# STM32MP13xx register map
File version: 1.5
CPU: CA7 r0p0, little endian, MPU, FPU, 4 interrupt priority bits
Registers are 32-bit, read-write, reset 0x0 unless marked. A register's access mark holds for its fields unless they carry their own. Offsets are from the block's base; [hi:lo] are bit positions; {n}, {i} and the like mark numbered series; 'fields as' and 'values as' point back to an identical list.

## SYSCFG
Base 0x50020000
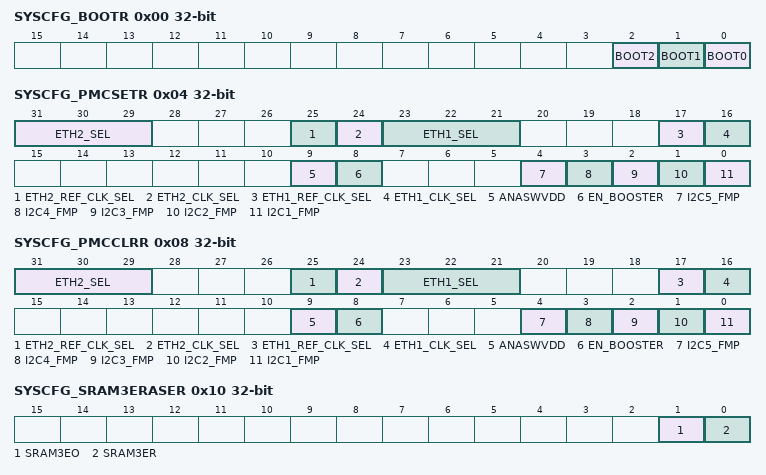
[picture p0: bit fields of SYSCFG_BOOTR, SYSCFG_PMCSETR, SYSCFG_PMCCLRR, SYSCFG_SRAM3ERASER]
0x00 SYSCFG_BOOTR ro (reset mask 0xFFFFFFF0) — SYSCFG boot pins control register
  [2] BOOT2 — BOOT2 pin value
    0=low (BOOT2 pin connected to VSS); 1=high (BOOT2 pin connected to VDD)
  [1] BOOT1 — BOOT1 pin value
    0=low (BOOT1 pin connected to VSS); 1=high (BOOT1 pin connected to VDD)
  [0] BOOT0 — BOOT0 pin value
    0=low (BOOT0 pin connected to VSS); 1=high (BOOT0 pin connected to VDD)
0x04 SYSCFG_PMCSETR — SYSCFG peripheral mode configuration set register
  [31:29] ETH2_SEL — Ethernet PHY interface selection. Set by software. Writing '0' has no effect. Set individual bits by writing '1â. Reading means: Note: Configuration must be done while the ETH is under reset and before enabling the ETH clocks This bit field is secure if ETH2 is set to secure in the ETZPC.
    0=MII; 1=RGMII; 4=RMII
  [25] ETH2_REF_CLK_SEL — Ethernet reference clock selection. Set by software. This bit is secure if ETH2 is set to secure in the ETZPC.
    0=Writing '0' has no effect, reading '0' means the receive clock (MII/RGMII mode) or the reference clock (RMII mode) comes from the ETH2_RX_CLK/ETH2_REF_CLK pin; 1=Writing '1' sets this bit, reading '1' means the reference clock (RMII mode) comes from the RCC
  [24] ETH2_CLK_SEL — Gigabit Ethernet 125Â MHz clock selection. Only useful with RGMII PHY. Set by software. This bit is secure if ETH2 is set to secure in the ETZPC.
    0=Writing '0' has no effect, reading '0' means the transmit clock comes from the ETHx_CLK125 pin; 1=Writing '1' sets this bit, reading '1' means the transmit clock comes from the RCC
  [23:21] ETH1_SEL — Ethernet PHY interface selection. Set by software. Writing '0' has no effect. Set individual bits by writing '1â. Reading means: Note: Configuration must be done while the ETH is under reset and before enabling the ETH clocks This bit field is secure if ETH1 is set to secure in the ETZPC.
    0=MII; 1=RGMII; 4=RMII
  [17] ETH1_REF_CLK_SEL — Ethernet reference clock selection. Set by software. This bit is secure if ETH1 is set to secure in the ETZPC.
    0=Writing '0' has no effect, reading '0' means the receive clock (MII/RGMII mode) or the reference clock (RMII mode) comes from the ETH1_RX_CLK/ETH1_REF_CLK pin; 1=Writing '1' sets this bit, reading '1' means the reference clock (RMII mode) comes from the RCC
  [16] ETH1_CLK_SEL — Gigabit Ethernet 125Â MHz clock selection. Only useful with RGMII PHY. Set by software. This bit is secure if ETH1 is set to secure in the ETZPC.
    values as ETH2_CLK_SEL
  [9] ANASWVDD — GPIO analog switch supply voltage selection Cleared by software. This bit is always secure.
    0=Writing '0' has no effect, reading '0' means analog switches are supplied by VDDA (if present and EN_BOOSTER=0) or by the booster output (EN_BOOSTER=1); 1=Writing '1' sets this bit, reading '1' means analog switches are supplied by VDD
  [8] EN_BOOSTER — GPIO analog switch supply voltage booster enable. Set by software. Used to reduce the total harmonic distortion of the I/O analog switches when VDDA and VDD supplies are below 2.7Â V. Activating the booster guarantees the AC performance on I/O analog switches. When activated the performance of the analog switch is the same over the full voltage range. This bit is always secure.
    0=Writing '0' has no effect, reading '0' means booster is disabled; 1=Writing '1' sets this bit, reading '1' means booster is enabled
  [4] I2C5_FMP — Fast mode plus (FM+) enable Set by software. This bit is secure if I2C5 is set to secure in the ETZPC.
    0=Writing '0' has no effect, reading '0' means I2C5 use is possible up to 400 kHz; 1=Writing '1' sets this bit, reading '1' means the I2C5 SCL & SDA I/Os are in Fast mode plus (FM+), when the corresponding alternate function is selected. The I/O low drive is enhanced to support up to 1 MHz.
  [3] I2C4_FMP — Fast Mode Plus (FM+) Enable Set by software. This bit is secure if I2C4 is set to secure in the ETZPC.
    0=Writing '0' has no effect, reading '0' means I2C4 use is possible up to 400 kHz; 1=Writing '1' sets this bit, reading '1' means the I2C4 SCL & SDA I/Os are in Fast mode plus (FM+), when the corresponding alternate function is selected. The I/O low drive is enhanced to support up to 1 MHz.
  [2] I2C3_FMP — Fast Mode Plus (FM+) Enable Set by software. This bit is secure if I2C3 is set to secure in the ETZPC.
    0=Writing '0' has no effect, reading '0' means I2C3 use is possible up to 400kHz; 1=Writing '1' sets this bit, reading '1' means the I2C3 SCL & SDA I/Os are in Fast mode plus (FM+), when the corresponding alternate function is selected. The I/O low drive is enhanced to support up to 1 MHz.
  [1] I2C2_FMP — Fast Mode Plus (FM+) Enable Set by software.
    0=Writing '0' has no effect, reading '0' means I2C2 use is possible up to 400 kHz; 1=Writing '1' sets this bit, reading '1' means the I2C2 SCL & SDA I/Os are in Fast mode plus (FM+), when the corresponding alternate function is selected. The I/O low drive is enhanced to support up to 1 MHz.
  [0] I2C1_FMP — Fast Mode Plus (FM+) Enable Set by software.
    0=Writing '0' has no effect, reading '0' means I2C1 use is possible up to 400 kHz; 1=Writing '1' sets this bit, reading '1' means the I2C1 SCL & SDA I/Os are in Fast mode plus (FM+), when the corresponding alternate function is selected. The I/O low drive is enhanced to support up to 1 MHz.
0x08 SYSCFG_PMCCLRR — SYSCFG peripheral mode configuration clear register
  [31:29] ETH2_SEL — Ethernet PHY interface selection. Set by software. Writing '0' has no effect. Clear individual bits by writing '1â. Reading means: Note: Configuration must be done while the ETH is under reset and before enabling the ETH clocks This bit field is secure if ETH2 is set to secure in the ETZPC.
    0=MII; 1=RGMII; 4=RMII
  [25] ETH2_REF_CLK_SEL — Ethernet reference clock selection. Set by software. This bit is secure if ETH2 is set to secure in the ETZPC.
    0='Writing '0' has no effect, reading '0' means the receive clock (MII/RGMII mode) or the reference clock (RMII mode) comes from the ETH2_RX_CLK/ETH2_REF_CLK pin; 1=Writing '1' clears this bit, reading '1' means the reference clock (RMII mode) comes from the RCC
  [24] ETH2_CLK_SEL — Gigabit Ethernet 125Â MHz clock selection. Only useful with RGMII PHY. Set by software. This bit is secure if ETH2 is set to secure in the ETZPC.
    0=Writing '0' has no effect, reading '0' means the transmit clock comes from the ETHx_CLK125 pin; 1=Writing '1' clears this bit, reading '1' means the transmit clock comes from the RCC
  [23:21] ETH1_SEL — Ethernet PHY interface selection. Set by software. Writing '0' has no effect. Clear individual bits by writing '1â. Reading means: Note: Configuration must be done while the ETH is under reset and before enabling the ETH clocks This bit field is secure if ETH1 is set to secure in the ETZPC.
    0=MII; 1=RGMII; 4=RMII
  [17] ETH1_REF_CLK_SEL — Ethernet reference clock selection. Set by software. This bit is secure if ETH1 is set to secure in the ETZPC
    0=Writing '0' has no effect, reading '0' means the receive clock (MII/RGMII mode) or the reference clock (RMII mode) comes from the ETH1_RX_CLK/ETH1_REF_CLK pin; 1=Writing '1' clears this bit, reading '1' means the reference clock (RMII mode) comes from the RCC
  [16] ETH1_CLK_SEL — Gigabit Ethernet 125Â MHz clock selection. Only useful with RGMII PHY. Set by software. This bit is secure if ETH1 is set to secure in the ETZPC
    values as ETH2_CLK_SEL
  [9] ANASWVDD — GPIO analog switch supply voltage selection Cleared by software. (if present and EN_BOOSTER=0) or by the booster output (EN_BOOSTER=1) This bit is always secure.
    0=Writing '0' has no effect, reading '0' means analog switches are supplied by VDDA; 1=Writing '1' clears this bit, reading '1' means analog switches are supplied by VDD
  [8] EN_BOOSTER — GPIO analog switch supply voltage booster enable. Cleared by software. Used to reduce the Total harmonic distortion of the I/O analog switches when VDDA and VDD supplies are below 2.7Â V. Activating the booster guarantees the AC performance on I/O analog switches. When activated the performance of the analog switch is the same over the full voltage range. This bit is always secure.
    0=Writing '0' has no effect, reading '0' means Booster is disabled; 1=Writing '1' clears this bit, reading '1' means Booster is enabled
  [4] I2C5_FMP — Fast Mode Plus (FM+) Enable Cleared by software. This bit is secure if I2C5 is set to secure in the ETZPC.
    0=Writing '0' has no effect, reading '0' means I2C5 usage is possible up to 400 kHz; 1=Writing '1' sets this bit, reading '1' means the I2C5 SCL & SDA I/Os are in Fast mode plus (FM+), when the corresponding alternate function is selected. The I/O low drive is enhanced to support up to 1 MHz.
  [3] I2C4_FMP — Fast Mode Plus (FM+) Enable Cleared by software. This bit is secure if I2C4 is set to secure in the ETZPC.
    0=Writing '0' has no effect, reading '0' means I2C4 usage is possible up to 400 kHz; 1=Writing '1' sets this bit, reading '1' means the I2C4 SCL & SDA I/Os are in Fast mode plus (FM+), when the corresponding alternate function is selected. The I/O low drive is enhanced to support up to 1 MHz.
  [2] I2C3_FMP — Fast Mode Plus (FM+) Enable Cleared by software. This bit is secure if I2C3 is set to secure in the ETZPC.
    0=Writing '0' has no effect, reading '0' means I2C3 usage is possible up to 400kHz; 1=Writing '1' sets this bit, reading '1' means the I2C3 SCL & SDA I/Os are in Fast mode plus (FM+), when the corresponding alternate function is selected. The I/O low drive is enhanced to support up to 1 MHz.
  [1] I2C2_FMP — Fast Mode Plus (FM+) Enable Cleared by software.
    0=Writing '0' has no effect, reading '0' means I2C2 usage is possible up to 400 kHz; 1=Writing '1' sets this bit, reading '1' means the I2C2 SCL & SDA I/Os are in Fast mode plus (FM+), when the corresponding alternate function is selected. The I/O low drive is enhanced to support up to 1 MHz.
  [0] I2C1_FMP — Fast Mode Plus (FM+) Enable Cleared by software.
    0=Writing '0' has no effect, reading '0' means I2C1 usage is possible up to 400 kHz; 1=Writing '1' sets this bit, reading '1' means the I2C1 SCL & SDA I/Os are in Fast mode plus (FM+), when the corresponding alternate function is selected. The I/O low drive is enhanced to support up to 1 MHz.
0x0C SYSCFG_BOOTCR — SYSCFG boot control register
  [0] BMEN — Boot mode enable This bit is writable only by secure privileged code. It should be used only during secure boot time, to ensure the timely execution of the firmware in charge of tamper management. When this bit is cleared from 1 to 0 while a potential tamper event is active, accesses to SRAM3 are automatically blocked (as defined above) and PKA, SAES, HASH and CRYP peripherals are reset. When a confirmed (not potential) tamper is raised by TAMP peripheral, SRAM3 is erased (as defined in TAMP) and PKA, SAES, HASH and CRYP peripherals are reset regardless of BMEN value.
    0=While a potential tamper event is raised by TAMP peripheral, multiple blocking and erase actions occur in the device. Among those actions the SRAM3 reads as zero and the writes to SRAM3 are ignored. Also a reset pulse is triggered on PKA, SAES, HASH and CRYP peripherals. See TAMP section for details.; 1=While a potential tamper event is raised by TAMP peripheral, read and write accesses to the SRAM3 are allowed, and the PKA, SAES, HASH and CRYP peripherals are not reset. The other blocking and erasing actions defined in TAMP peripheral are not impacted.
0x10 SYSCFG_SRAM3ERASER access per field — SYSCFG SRAM3 erase register
  [1] SRAM3EO ro — SRAM3 erase ongoing This bit indicates whether an erase of SRAM3 is being carried out, whatever the trigger (tamper or software).
    0=no erase ongoing; 1=erase ongoing
  [0] SRAM3ER rw — SRAM3 erase request This bit is set by software and automatically reset by hardware at the end of the erase operation. It can only be set if the correct unlock sequence has previously been written to the SYSCFG_SRAM3KR.KEY[7:0] register field. This bit is secure if SRAM3 is set to secure in the ETZPC.
0x14 SYSCFG_SRAM3KR wo — SYSCFG SRAM3 erase key register
  [7:0] KEY — SRAM3 software erase key Writing the following sequence to KEY[7:0] unlocks the SRAM3 software erase feature: 0xCA 0x53 Writing any other value locks the feature.
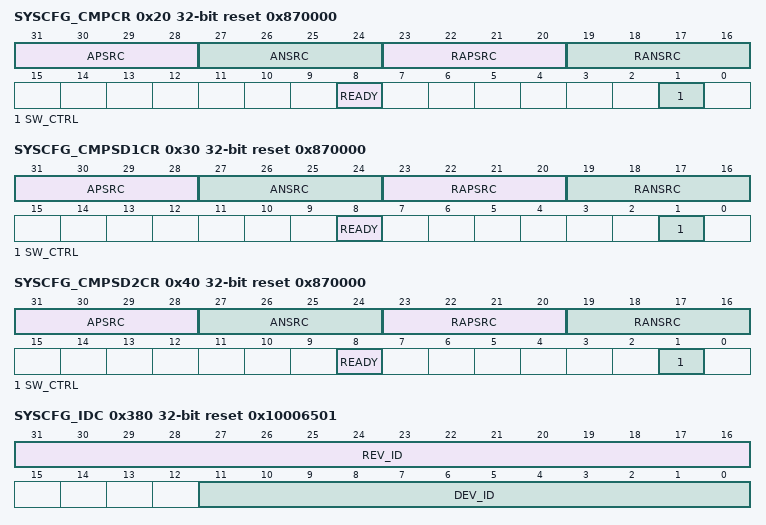
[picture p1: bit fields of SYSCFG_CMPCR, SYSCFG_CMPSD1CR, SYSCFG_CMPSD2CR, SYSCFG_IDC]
0x20 SYSCFG_CMPCR access per field reset 0x870000 (reset mask 0xFFFFFF) — SYSCFG main compensation cell control register
  [31:28] APSRC ro — PMOS I/O compensation value provided by compensation cell Value sent to I/O compensation when SW_CTRL = 0 and READY = 1.
  [27:24] ANSRC ro — NMOS I/O compensation value provided by compensation cell Value sent to I/Os when SW_CTRL = 0 and READY = 1.
  [23:20] RAPSRC rw — PMOS I/O Compensation value sent to I/Os when SW_CTRL = 1 .... .... Note: If compensation is needed, it is recommended to use automatic compensation
    1=maximum compensation of fast conditions; 8=compensation for typical conditions; 14=maximum compensation of slow conditions
  [19:16] RANSRC rw — NMOS I/O compensation value sent to I/Os when SW_CTRL = 1 .... .... Note: If compensation is needed, it is recommended to use automatic compensation
    1=maximum compensation of slow conditions; 7=compensation for typical conditions; 14=maximum compensation of fast conditions
  [8] READY ro — Compensation cell ready flag
    0=I/O compensation cell not ready; 1=I/O compensation cell ready, the values of APSRC[3:0] and ANSRC[3:0] are valid
  [1] SW_CTRL rw — Compensation software control Note: SW_CTRL = 0 is not taken into account until READY = 1. This means that whatever SW_CTRL value, the RANSRC[3:0] and RAPSRC[3:0] are used for I/O compensation when the compensation cell is in power down (EN = 0, which is the case after a reset).
    0=I/O compensation values come from compensation values in ANSRC[3:0] and APSRC[3:0]; 1=I/O compensation values come from RANSRC[3:0] and RAPSRC[3:0] register values
0x24 SYSCFG_CMPENSETR — SYSCFG main compensation cell enable set register
  [0] EN — Compensation cell enable Set by software. Note: The CSI oscillator must be enabled and ready (controlled in RCC) before EN can be set to 1. Similarly, the CSI oscillator can be disabled only if EN is set to 0.
    0=power_down (Writing '0' has no effect, reading '0â means I/O compensation cell in power-down mode); 1=enabled (Writing '1' enables I/O compensation cell, reading '1â means I/O compensation cell is enabled)
0x28 SYSCFG_CMPENCLRR — SYSCFG main compensation cell enable set register
  [0] EN — Compensation cell enable Cleared by software. Note: The CSI oscillator must be enabled and ready (controlled in RCC) before EN can be set to 1. Similarly, the CSI oscillator can be disabled only if EN is set to 0.
    0=power_down (Writing '0' has no effect, reading '0â means I/O compensation cell in powerdown mode); 1=enabled (Writing '1' clears EN bit, reading '1â means I/O compensation cell is enabled)
0x2C SYSCFG_CBR — SYSCFG control timer break register
  [2] PVDL — PVD lock enable bit This bit is set by software and cleared only by a system reset. It can be used to enable and lock the PVD connection to TIM1/8/15/16/17 Break input, as well as the PVDE and PLS[2:0] in the PWR_CR1 register.
    0=PVD interrupt disconnected from TIM1/8/15/16/17 Break input. PVDE and PLS[2:0] bits can be programmed by the application.; 1=PVD interrupt connected to TIM1/8/15/16/17 Break input. PVDE and PLS[2:0] bits are read only.
0x30 SYSCFG_CMPSD1CR access per field reset 0x870000 (reset mask 0xFFFFFF) — SYSCFG VDDSD1 compensation cell control register
  [31:28] APSRC ro — PMOS I/O Compensation value provided by compensation cell Value sent to I/Os compensation when SW_CTRL = 0 and READY = 1.
  [27:24] ANSRC ro — NMOS I/O Compensation value provided by compensation cell Value sent to I/Os when SW_CTRL = 0 and READY = 1.
  [23:20] RAPSRC rw — PMOS I/O compensation value sent to I/Os when SW_CTRL = 1 .... .... Note: If compensation is needed, it is recommended to use automatic compensation This bit field is secure if SDMMC1 is set to secure in the ETZPC.
    values as SYSCFG_CMPCR.RAPSRC
  [19:16] RANSRC rw — NMOS I/O compensation value sent to I/Os when SW_CTRL = 1 .... .... Note: If compensation is needed, it is recommended to use automatic compensation This bit field is secure if SDMMC1 is set to secure in the ETZPC.
    values as SYSCFG_CMPCR.RANSRC
  [8] READY ro — Compensation cell ready flag
    values as SYSCFG_CMPCR.READY
  [1] SW_CTRL rw — Compensation software control Note: SW_CTRL = 0 is not taken into account until READY = 1. This means that whatever SW_CTRL value, the RANSRC[3:0] and RAPSRC[3:0] are used for I/O compensation when the compensation cell is in power down (EN = 0, which is the case after a reset). This bit is secure if SDMMC1 is set to secure in the ETZPC.
    values as SYSCFG_CMPCR.SW_CTRL
0x34 SYSCFG_CMPSD1ENSETR — SYSCFG VDDSD1 compensation cell enable set register
  [0] EN — Compensation cell enable Set by software. Note: The CSI oscillator must be enabled and ready (controlled in RCC) before EN can be set to 1. Similarly, the CSI oscillator can be disabled only if MPU_EN is set to 0. This bit is secure if SDMMC1 is set to secure in the ETZPC.
    values as SYSCFG_CMPENSETR.EN
0x38 SYSCFG_CMPSD1ENCLRR — SYSCFG VDDSD1 compensation cell enable clear register
  [0] EN — Compensation cell enable Cleared by software. Note: The CSI oscillator must be enabled and ready (controlled in RCC) before EN can be set to 1. Similarly, the CSI oscillator can be disabled only if EN is set to 0. This bit is secure if SDMMC1 is set to secure in the ETZPC.
    0=power_down (Writing '0' has no effect, reading '0â means I/O compensation cell in powerdown mode); 1=enabled (Writing '1' clear EN bit, reading '1â means I/O compensation cell is enabled)
0x40 SYSCFG_CMPSD2CR access per field reset 0x870000 (reset mask 0xFFFFFF) — SYSCFG VDDSD2 compensation cell control register
  [31:28] APSRC ro — PMOS I/O Compensation value provided by compensation cell Value sent to I/Os compensation when SW_CTRL = 0 and READY = 1
  [27:24] ANSRC ro — NMOS I/O Compensation value provided by compensation cell Value sent to I/Os when SW_CTRL = 0 and READY = 1
  [23:20] RAPSRC rw — PMOS I/O compensation value sent to I/Os when SW_CTRL = 1 .... .... Note: If compensation is needed, it is recommended to use automatic compensation This bit field is secure if SDMMC2 is set to secure in the ETZPC.
    values as SYSCFG_CMPCR.RAPSRC
  [19:16] RANSRC rw — NMOS I/O compensation value sent to I/Os when SW_CTRL = 1 .... .... Note: If compensation is needed, it is recommended to use automatic compensation This bit field is secure if SDMMC2 is set to secure in the ETZPC.
    values as SYSCFG_CMPCR.RANSRC
  [8] READY ro — Compensation cell ready flag
    values as SYSCFG_CMPCR.READY
  [1] SW_CTRL rw — Compensation Software Control Note: SW_CTRL = 0 is not taken into account until READY = 1. This means that whatever SW_CTRL value, the RANSRC[3:0] and RAPSRC[3:0] are used for I/O compensation when the compensation cell is in power down (EN = 0, which is the case after a reset). This bit is secure if SDMMC2 is set to secure in the ETZPC
    values as SYSCFG_CMPCR.SW_CTRL
0x44 SYSCFG_CMPSD2ENSETR — SYSCFG VDDSD2 compensation cell enable set register
  [0] EN — Compensation cell enable Set by software. Note: The CSI oscillator must be enabled and ready (controlled in RCC) before EN can be set to 1. Similarly, the CSI oscillator can be disabled only if EN is set to 0. This bit is secure if SDMMC2 is set to secure in the ETZPC.
    values as SYSCFG_CMPENSETR.EN
0x48 SYSCFG_CMPSD2ENCLRR — SYSCFG VDDSD2 compensation cell enable clear register
  [0] EN — Compensation cell enable Cleared by software. Note: The CSI oscillator must be enabled and ready (controlled in RCC) before EN can be set to 1. Similarly, the CSI oscillator can be disabled only if EN is set to 0. This bit is secure if SDMMC2 is set to secure in the ETZPC.
    0=power_down (Writing '0' has no effect, reading '0â means I/O compensation cell in powerdown mode); 1=enabled (Writing '1' clear MPU_EN bit, reading '1â means I/O compensation cell is enabled)
{0x50+4i} SYSCFG_HSLVEN{i}R wo (i=0..11) — SYSCFG high-speed low-voltage enable register {i}
  [15:0] HSLVEN — High-speed low-voltage I/O mode enable. Controls the speed of _h and _vh type I/Os associated with an interface when that interface is selected in the AFMUX When writing: Others: disables high speed mode When reading:
    0x1018=enables high speed mode; 1=high speed mode enabled; 0=high speed mode disabled
0x380 SYSCFG_IDC ro reset 0x10006501 — SYSCFG identity code register
  [31:16] REV_ID — device revision 0x1000 = Rev. 1
  [11:0] DEV_ID — device ID
    0x501=STM32MP13xx
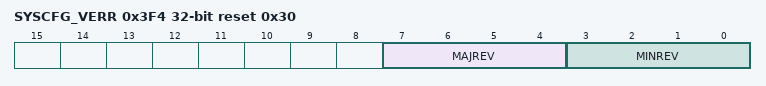
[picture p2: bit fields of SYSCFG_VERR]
0x3F4 SYSCFG_VERR ro reset 0x30 — SYSCFG version register
  [7:4] MAJREV — Major revision These bits return the SYSCFG major revision. Major revision is 3.
  [3:0] MINREV — Minor revision These bits return the SYSCFG minor revision. Minor revision is 0.
0x3F8 SYSCFG_IPIDR ro reset 0x30001 — SYSCFG identification register
  [31:0] ID — SYSCFG identifier These bits return the SYSCFG identifier value.
0x3FC SYSCFG_SIDR ro reset 0xA3C5DD01 — SYSCFG size identification register
  [31:0] SID — Size identification These bits return the size of the memory region allocated to SYSCFG registers.
